# PIC32MX170F512L register map
Vendor: Microchip
Registers are 32-bit, read-write, reset 0x0 unless marked. A register's access mark holds for its fields unless they carry their own. Addresses are absolute, and some are shared; only a register's first bit layout is shown; [hi:lo] are bit positions.

## SPI3
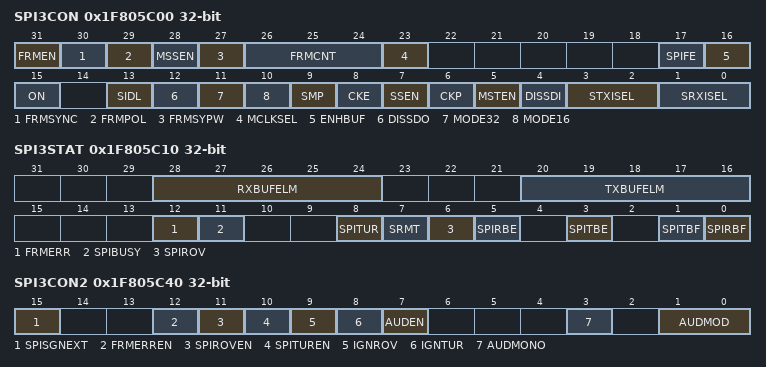
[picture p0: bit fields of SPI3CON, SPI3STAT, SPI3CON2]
0x1F805C00 SPI3CON reset not defined — (power-on value 00000000x-----0000000000000x0000)
  [31] FRMEN, [30] FRMSYNC, [29] FRMPOL, [28] MSSEN, [27] FRMSYPW, [26:24] FRMCNT, [23] MCLKSEL, [17] SPIFE, [16] ENHBUF, [15] ON, [13] SIDL, [12] DISSDO, [11] MODE32, [10] MODE16, [9] SMP, [8] CKE, [7] SSEN, [6] CKP, [5] MSTEN, [4] DISSDI, [3:2] STXISEL, [1:0] SRXISEL
0x1F805C10 SPI3STAT reset not defined — (power-on value ---00000---00000---x0--0000-0-00)
  [28:24] RXBUFELM ro, [20:16] TXBUFELM ro, [12] FRMERR, [11] SPIBUSY ro, [8] SPITUR ro, [7] SRMT ro, [6] SPIROV ro, [5] SPIRBE ro, [3] SPITBE ro, [1] SPITBF ro, [0] SPIRBF ro
0x1F805C20 SPI3BUF reset not defined — (power-on value xxxxxxxxxxxxxxxxxxxxxxxxxxxxxxxx)
0x1F805C30 SPI3BRG reset not defined — (power-on value -------------------xxxxxxxxxxxxx)
  [12:0] SPI3BRG
0x1F805C40 SPI3CON2 reset not defined — (power-on value ----------------x--xxxxxx---x-xx)
  [15] SPISGNEXT, [12] FRMERREN, [11] SPIROVEN, [10] SPITUREN, [9] IGNROV, [8] IGNTUR, [7] AUDEN, [3] AUDMONO, [1:0] AUDMOD

## SPI4
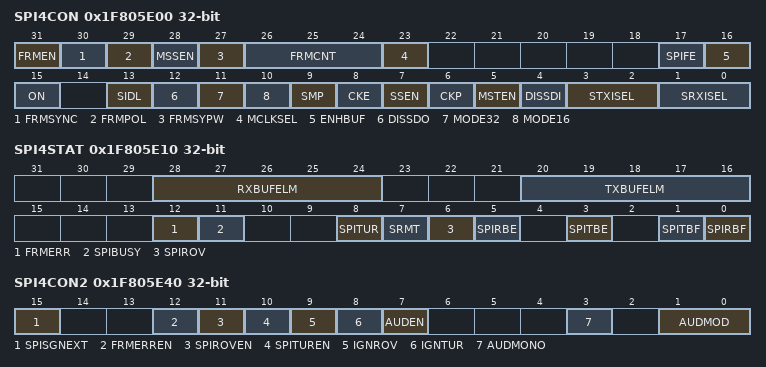
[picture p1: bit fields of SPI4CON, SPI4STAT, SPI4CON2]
0x1F805E00 SPI4CON reset not defined — (power-on value 00000000x-----0000000000000x0000)
  [31] FRMEN, [30] FRMSYNC, [29] FRMPOL, [28] MSSEN, [27] FRMSYPW, [26:24] FRMCNT, [23] MCLKSEL, [17] SPIFE, [16] ENHBUF, [15] ON, [13] SIDL, [12] DISSDO, [11] MODE32, [10] MODE16, [9] SMP, [8] CKE, [7] SSEN, [6] CKP, [5] MSTEN, [4] DISSDI, [3:2] STXISEL, [1:0] SRXISEL
0x1F805E10 SPI4STAT reset not defined — (power-on value ---00000---00000---x0--0000-0-00)
  [28:24] RXBUFELM ro, [20:16] TXBUFELM ro, [12] FRMERR, [11] SPIBUSY ro, [8] SPITUR ro, [7] SRMT ro, [6] SPIROV ro, [5] SPIRBE ro, [3] SPITBE ro, [1] SPITBF ro, [0] SPIRBF ro
0x1F805E20 SPI4BUF reset not defined — (power-on value xxxxxxxxxxxxxxxxxxxxxxxxxxxxxxxx)
0x1F805E30 SPI4BRG reset not defined — (power-on value -------------------xxxxxxxxxxxxx)
  [12:0] SPI4BRG
0x1F805E40 SPI4CON2 reset not defined — (power-on value ----------------x--xxxxxx---x-xx)
  [15] SPISGNEXT, [12] FRMERREN, [11] SPIROVEN, [10] SPITUREN, [9] IGNROV, [8] IGNTUR, [7] AUDEN, [3] AUDMONO, [1:0] AUDMOD

## UART1
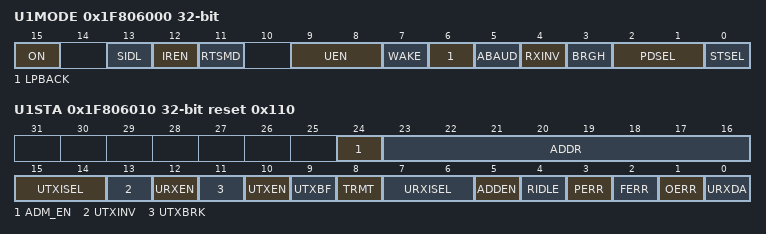
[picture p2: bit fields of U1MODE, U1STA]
0x1F806000 U1MODE
  [15] ON, [13] SIDL, [12] IREN, [11] RTSMD, [9:8] UEN, [7] WAKE, [6] LPBACK, [5] ABAUD, [4] RXINV, [3] BRGH, [2:1] PDSEL, [0] STSEL
0x1F806010 U1STA reset 0x110
  [24] ADM_EN
  [23:16] ADDR
  [15:14] UTXISEL
  [13] UTXINV
  [12] URXEN
  [11] UTXBRK
  [10] UTXEN
  [9] UTXBF ro
  [8] TRMT ro
  [7:6] URXISEL
  [5] ADDEN
  [4] RIDLE ro
  [3] PERR ro
  [2] FERR ro
  [1] OERR — (can only be cleared)
  [0] URXDA ro
0x1F806020 U1TXREG reset not defined — (power-on value -----------------------xxxxxxxxx)
  [8:0] U1TXREG
0x1F806030 U1RXREG ro
  [8:0] U1RXREG
0x1F806040 U1BRG
  [15:0] BRG

## UART2
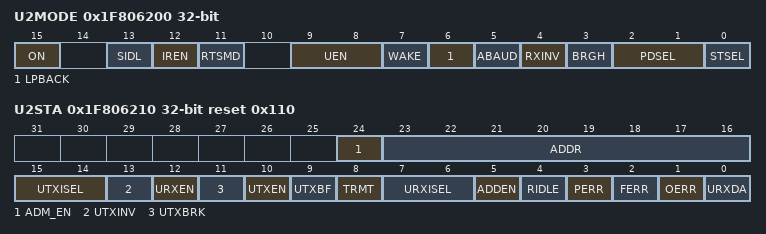
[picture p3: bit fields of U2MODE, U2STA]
0x1F806200 U2MODE
  [15] ON, [13] SIDL, [12] IREN, [11] RTSMD, [9:8] UEN, [7] WAKE, [6] LPBACK, [5] ABAUD, [4] RXINV, [3] BRGH, [2:1] PDSEL, [0] STSEL
0x1F806210 U2STA reset 0x110
  [24] ADM_EN
  [23:16] ADDR
  [15:14] UTXISEL
  [13] UTXINV
  [12] URXEN
  [11] UTXBRK
  [10] UTXEN
  [9] UTXBF ro
  [8] TRMT ro
  [7:6] URXISEL
  [5] ADDEN
  [4] RIDLE ro
  [3] PERR ro
  [2] FERR ro
  [1] OERR — (can only be cleared)
  [0] URXDA ro
0x1F806220 U2TXREG reset not defined — (power-on value -----------------------xxxxxxxxx)
  [8:0] U2TXREG
0x1F806230 U2RXREG ro
  [8:0] U2RXREG
0x1F806240 U2BRG
  [15:0] BRG

## UART3
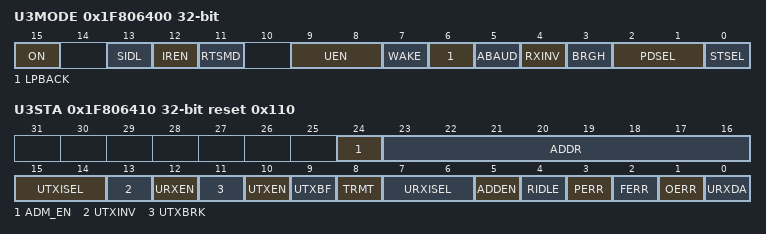
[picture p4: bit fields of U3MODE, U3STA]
0x1F806400 U3MODE
  [15] ON, [13] SIDL, [12] IREN, [11] RTSMD, [9:8] UEN, [7] WAKE, [6] LPBACK, [5] ABAUD, [4] RXINV, [3] BRGH, [2:1] PDSEL, [0] STSEL
0x1F806410 U3STA reset 0x110
  [24] ADM_EN
  [23:16] ADDR
  [15:14] UTXISEL
  [13] UTXINV
  [12] URXEN
  [11] UTXBRK
  [10] UTXEN
  [9] UTXBF ro
  [8] TRMT ro
  [7:6] URXISEL
  [5] ADDEN
  [4] RIDLE ro
  [3] PERR ro
  [2] FERR ro
  [1] OERR — (can only be cleared)
  [0] URXDA ro
0x1F806420 U3TXREG reset not defined — (power-on value -----------------------xxxxxxxxx)
  [8:0] U3TXREG
0x1F806430 U3RXREG ro
  [8:0] U3RXREG
0x1F806440 U3BRG
  [15:0] BRG
